# LAN9255ZMX020 register map
Vendor: Microchip
Registers are 32-bit, read-write, reset 0x0 unless marked. A register's access mark holds for its fields unless they carry their own. Addresses are absolute, and some are shared; only a register's first bit layout is shown; [hi:lo] are bit positions; {n}, {i} and the like mark numbered series; 'fields as' and 'values as' point back to an identical list.

## AES
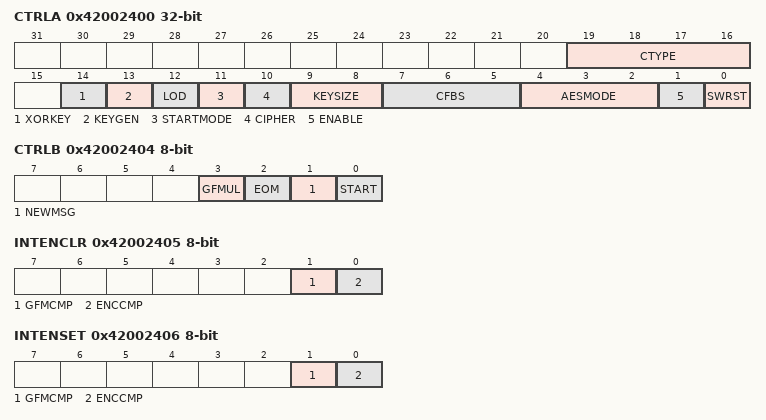
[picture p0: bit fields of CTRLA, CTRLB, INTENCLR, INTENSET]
0x42002400 CTRLA
  [19:16] CTYPE — Counter Measure Type
  [14] XORKEY — XOR Key Operation
    0=NONE (No effect); 1=XOR (The user keyword gets XORed with the previous keyword register content.)
  [13] KEYGEN — Last Key Generation
    0=NONE (No effect); 1=LAST (Start Computation of the last NK words of the expanded key)
  [12] LOD — Last Output Data Mode
    0=NONE (No effect); 1=LAST (Start encryption in Last Output Data mode)
  [11] STARTMODE — Start Mode Select
    0=MANUAL (Start Encryption / Decryption in Manual mode); 1=AUTO (Start Encryption / Decryption in Auto mode)
  [10] CIPHER — Cipher Mode
    0=DEC (Decryption); 1=ENC (Encryption)
  [9:8] KEYSIZE — Encryption Key Size
    0=128BIT (128-bit Key for Encryption / Decryption); 1=192BIT (192-bit Key for Encryption / Decryption); 2=256BIT (256-bit Key for Encryption / Decryption)
  [7:5] CFBS — Cipher Feedback Block Size
    0=128BIT (128-bit Input data block for Encryption/Decryption in Cipher Feedback mode); 1=64BIT (64-bit Input data block for Encryption/Decryption in Cipher Feedback mode); 2=32BIT (32-bit Input data block for Encryption/Decryption in Cipher Feedback mode); 3=16BIT (16-bit Input data block for Encryption/Decryption in Cipher Feedback mode); 4=8BIT (8-bit Input data block for Encryption/Decryption in Cipher Feedback mode)
  [4:2] AESMODE — AES Modes of operation
    0=ECB (Electronic code book mode); 1=CBC (Cipher block chaining mode); 2=OFB (Output feedback mode); 3=CFB (Cipher feedback mode); 4=COUNTER (Counter mode); 5=CCM (CCM mode); 6=GCM (Galois counter mode)
  [1] ENABLE
  [0] SWRST — Software Reset
0x42002404 CTRLB 8-bit
  [3] GFMUL — GF Multiplication
  [2] EOM — End of message
  [1] NEWMSG — New message
  [0] START — Start Encryption/Decryption
0x42002405 INTENCLR 8-bit
  [1] GFMCMP — GF Multiplication Complete Interrupt Enable
  [0] ENCCMP — Encryption Complete Interrupt Enable
0x42002406 INTENSET 8-bit
  fields as INTENCLR
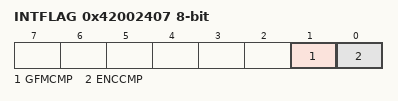
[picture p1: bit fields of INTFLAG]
0x42002407 INTFLAG 8-bit
  [1] GFMCMP — GF Multiplication Complete
  [0] ENCCMP — Encryption Complete
0x42002408 DATABUFPTR 8-bit
  [1:0] INDATAPTR — Input Data Pointer
0x42002409 DBGCTRL 8-bit
  [0] DBGRUN — Debug Run
{0x4200240C+4i} KEYWORD{i} wo (i=0..7)
0x42002438 INDATA
{0x4200243C+4i} INTVECTV{i} wo (i=0..3)
{0x4200245C+4i} HASHKEY{i} (i=0..3)
{0x4200246C+4i} GHASH{i} (i=0..3)
0x42002480 CIPLEN
0x42002484 RANDSEED

## TRNG
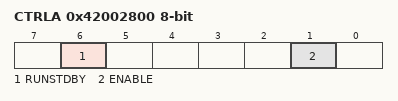
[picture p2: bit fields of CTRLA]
0x42002800 CTRLA 8-bit
  [6] RUNSTDBY — Run in Standby
  [1] ENABLE
0x42002804 EVCTRL 8-bit
  [0] DATARDYEO — Data Ready Event Output
0x42002808 INTENCLR 8-bit
  [0] DATARDY — Data Ready Interrupt Enable
0x42002809 INTENSET 8-bit
  [0] DATARDY — Data Ready Interrupt Enable
0x4200280A INTFLAG 8-bit
  [0] DATARDY — Data Ready Interrupt Flag
0x42002820 DATA ro
  [31:0] DATA — Output Data

## ICM
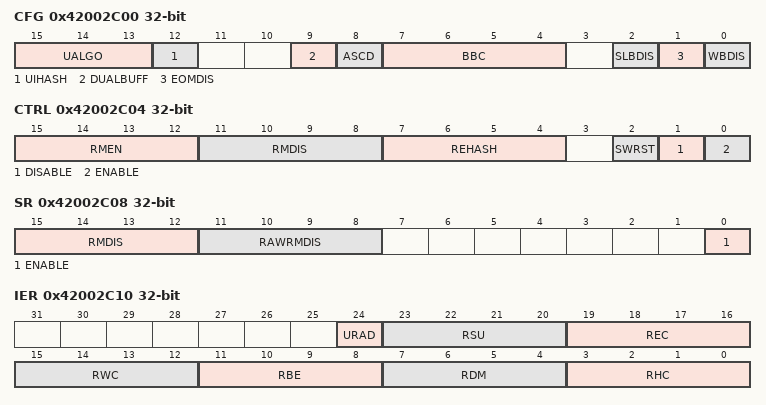
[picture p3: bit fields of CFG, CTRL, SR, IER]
0x42002C00 CFG
  [15:13] UALGO — User SHA Algorithm
    0=SHA1 (SHA1 Algorithm); 1=SHA256 (SHA256 Algorithm); 4=SHA224 (SHA224 Algorithm)
  [12] UIHASH — User Initial Hash Value
  [9] DUALBUFF — Dual Input Buffer
  [8] ASCD — Automatic Switch To Compare Digest
  [7:4] BBC — Bus Burden Control
  [2] SLBDIS — Secondary List Branching Disable
  [1] EOMDIS — End of Monitoring Disable
  [0] WBDIS — Write Back Disable
0x42002C04 CTRL wo reset not defined
  [15:12] RMEN — Region Monitoring Enable
  [11:8] RMDIS — Region Monitoring Disable
  [7:4] REHASH — Recompute Internal Hash
  [2] SWRST — Software Reset
  [1] DISABLE — ICM Disable Register
  [0] ENABLE — ICM Enable
0x42002C08 SR ro
  [15:12] RMDIS — Region Monitoring Disabled Status
  [11:8] RAWRMDIS — RAW Region Monitoring Disabled Status
  [0] ENABLE — ICM Controller Enable Register
0x42002C10 IER wo reset not defined
  [24] URAD — Undefined Register Access Detection Interrupt Enable
  [23:20] RSU — Region Status Updated Interrupt Disable
  [19:16] REC — Region End bit Condition Detected Interrupt Enable
  [15:12] RWC — Region Wrap Condition detected Interrupt Enable
  [11:8] RBE — Region Bus Error Interrupt Enable
  [7:4] RDM — Region Digest Mismatch Interrupt Enable
  [3:0] RHC — Region Hash Completed Interrupt Enable
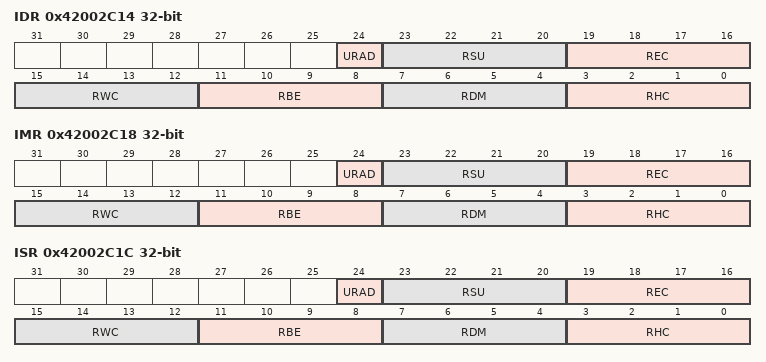
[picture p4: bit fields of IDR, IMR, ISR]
0x42002C14 IDR wo
  [24] URAD — Undefined Register Access Detection Interrupt Disable
  [23:20] RSU — Region Status Updated Interrupt Disable
  [19:16] REC — Region End bit Condition detected Interrupt Disable
  [15:12] RWC — Region Wrap Condition Detected Interrupt Disable
  [11:8] RBE — Region Bus Error Interrupt Disable
  [7:4] RDM — Region Digest Mismatch Interrupt Disable
  [3:0] RHC — Region Hash Completed Interrupt Disable
0x42002C18 IMR ro
  [24] URAD — Undefined Register Access Detection Interrupt Mask
  [23:20] RSU — Region Status Updated Interrupt Mask
  [19:16] REC — Region End bit Condition Detected Interrupt Mask
  [15:12] RWC — Region Wrap Condition Detected Interrupt Mask
  [11:8] RBE — Region Bus Error Interrupt Mask
  [7:4] RDM — Region Digest Mismatch Interrupt Mask
  [3:0] RHC — Region Hash Completed Interrupt Mask
0x42002C1C ISR ro
  [24] URAD — Undefined Register Access Detection Status
  [23:20] RSU — Region Status Updated Detected
  [19:16] REC — Region End bit Condition Detected
  [15:12] RWC — Region Wrap Condition Detected
  [11:8] RBE — Region Bus Error
  [7:4] RDM — Region Digest Mismatch
  [3:0] RHC — Region Hash Completed
0x42002C20 UASR ro
  [2:0] URAT — Undefined Register Access Trace
    0=UNSPEC_STRUCT_MEMBER (Unspecified structure member set to one detected when the descriptor is loaded); 1=CFG_MODIFIED (CFG modified during active monitoring); 2=DSCR_MODIFIED (DSCR modified during active monitoring); 3=HASH_MODIFIED (HASH modified during active monitoring); 4=READ_ACCESS (Write-only register read access)
0x42002C30 DSCR
  [31:6] DASA — Descriptor Area Start Address
0x42002C34 HASH
  [31:7] HASA — Hash Area Start Address
{0x42002C38+4i} UIHVAL{i} wo (i=0..7)
  [31:0] VAL — Initial Hash Value
